AUTOSAR XML (schema 322)
package /ComponentType
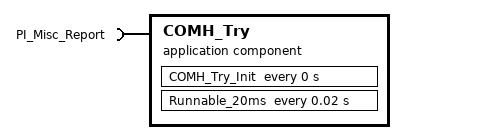
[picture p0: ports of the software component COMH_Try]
  application software component type COMH_Try
    require port PI_Misc_Report: required-interface=PI_Misc_Report
      required-com-specs:
        data-element=DE_DOORD, handle-invalid=DONT-INVALIDATE, init-value=C_DOORD
        data-element=DE_DOORL, handle-invalid=DONT-INVALIDATE, init-value=C_DOORL
        data-element=DE_DOORP, handle-invalid=DONT-INVALIDATE, init-value=C_DOORP
        data-element=DE_DOORR, handle-invalid=DONT-INVALIDATE, init-value=C_DOORR
        data-element=DE_TRUNK, handle-invalid=DONT-INVALIDATE, init-value=C_TRUNK
  internal behavior COMH_Try_InternalBehavior: component=COMH_Try, port-api-option{enable-take-address=false, indirect-api=false, port=PI_Misc_Report}
    timing event COMH_Try_InitEvent: start-on-event=COMH_Try_Init, period=0
    timing event TMT_Runnable_20ms: start-on-event=Runnable_20ms, period=0.02
    runnable COMH_Try_Init
    runnable Runnable_20ms
      5 x data receive point:
        REC_PI_Misc_Report_DE_DOORD: data-element=PI_Misc_Report.DE_DOORD
        REC_PI_Misc_Report_DE_DOORL: data-element=PI_Misc_Report.DE_DOORL
        REC_PI_Misc_Report_DE_DOORP: data-element=PI_Misc_Report.DE_DOORP
        REC_PI_Misc_Report_DE_DOORR: data-element=PI_Misc_Report.DE_DOORR
        REC_PI_Misc_Report_DE_TRUNK: data-element=PI_Misc_Report.DE_TRUNK
  swc implementation COMH_Try_Implementation: behavior=COMH_Try_InternalBehavior
    code-descriptors:
      code Code: type=SRC
package /Constant
  5 x constant specification:
    C_DOORD
      value:
        boolean literal C_DOORD: type=DT_DOORD, value=false
    C_DOORL
      value:
        boolean literal C_DOORL: type=DT_DOORL, value=false
    C_DOORP
      value:
        boolean literal C_DOORP: type=DT_DOORP, value=false
    C_DOORR
      value:
        boolean literal C_DOORR: type=DT_DOORR, value=false
    C_TRUNK
      value:
        boolean literal C_TRUNK: type=DT_TRUNK, value=false
package /DataType
  5 x boolean type:
    DT_DOORD
    DT_DOORL
    DT_DOORP
    DT_DOORR
    DT_TRUNK
package /PortInterface
  sender receiver interface PI_Misc_Report
    5 x data:
      DE_DOORD: type=DT_DOORD
      DE_DOORL: type=DT_DOORL
      DE_DOORP: type=DT_DOORP
      DE_DOORR: type=DT_DOORR
      DE_TRUNK: type=DT_TRUNK
